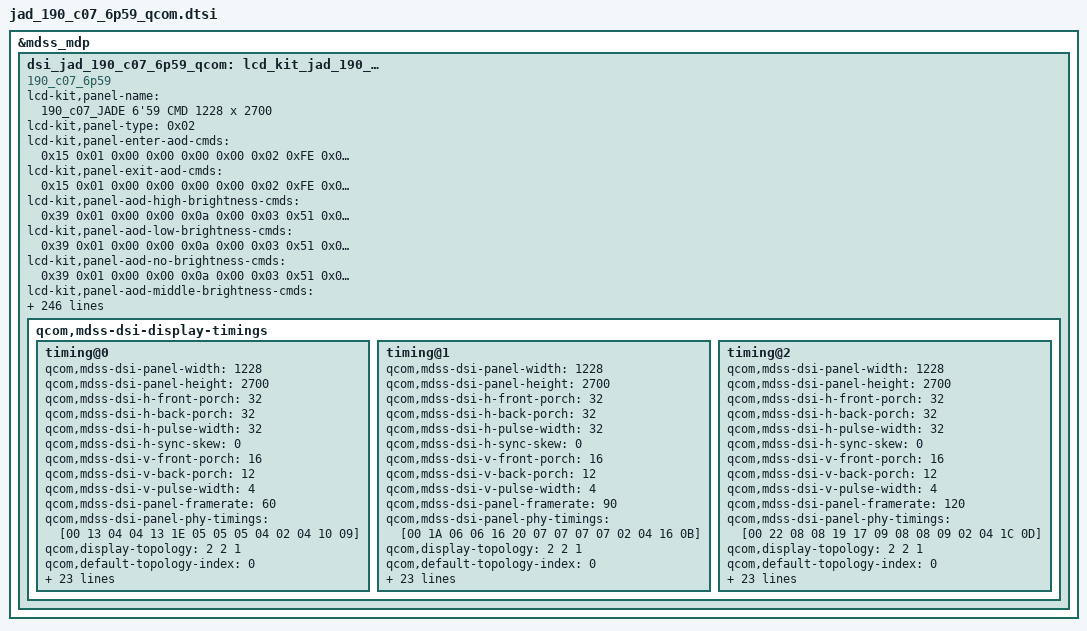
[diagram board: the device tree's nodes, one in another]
/* Copyright (c) 2013, The Linux Foundation. All rights reserved.
 *
 * This program is free software; you can redistribute it and/or modify
 * it under the terms of the GNU General Public License version 2 and
 * only version 2 as published by the Free Software Foundation.
 *
 * This program is distributed in the hope that it will be useful,
 * but WITHOUT ANY WARRANTY; without even the implied warranty of
 * MERCHANTABILITY or FITNESS FOR A PARTICULAR PURPOSE.  See the
 * GNU General Public License for more details.
 */

/*-------------------------------------------------------------------------
 * This file is autogenerated file using gcdb parser. Please do not edit it.
 * Update input XML file to add a new entry or update variable in this file
 * VERSION = 1.1
 *-----------------------------------------------------------------------*/
&mdss_mdp {
	dsi_jad_190_c07_6p59_qcom: lcd_kit_jad_190_c07_6p59_qcom {
		compatible = "190_c07_6p59";
		lcd-kit,panel-name = "190_c07_JADE 6'59 CMD 1228 x 2700";
		lcd-kit,panel-type = <0x02>;
		lcd-kit,panel-enter-aod-cmds = <0x15 0x01 0x00 0x00 0x00 0x00 0x02 0xFE 0x00
			0x05 0x01 0x00 0x00 0x00 0x00 0x01 0x39>;
		lcd-kit,panel-exit-aod-cmds = <0x15 0x01 0x00 0x00 0x00 0x00 0x02 0xFE 0x00
			0x05 0x01 0x00 0x00 0x00 0x00 0x01 0x38>;
		lcd-kit,panel-aod-high-brightness-cmds = <0x39 0x01 0x00 0x00 0x0a 0x00 0x03 0x51 0x0F 0xFE>;
		lcd-kit,panel-aod-low-brightness-cmds = <0x39 0x01 0x00 0x00 0x0a 0x00 0x03 0x51 0x01 0x64>;
		lcd-kit,panel-aod-no-brightness-cmds = <0x39 0x01 0x00 0x00 0x0a 0x00 0x03 0x51 0x00 0x00>;
		lcd-kit,panel-aod-middle-brightness-cmds = <0x39 0x01 0x00 0x00 0x0a 0x00 0x03 0x51 0x07 0x5F>;
		lcd-kit,panel-aod-off-cmds-state = "dsi_lp_mode";
		lcd-kit,pcd-check-reg-cmds = <0x01>;
		lcd-kit,check-reg-on-cmds = <0x06 0x01 0x00 0x00 0x0a 0x00 0x01 0x0a>;
		lcd-kit,check-reg-on-value = <0x9c>;
		lcd-kit,check-aod-reg-on-cmds = <0x06 0x01 0x00 0x00 0x0a 0x00 0x01 0x0a>;
		lcd-kit,check-aod-reg-on-value = <0xdc>;
		lcd-kit,check-reg-off-cmds = <0x06 0x01 0x00 0x00 0x0a 0x00 0x01 0x0a>;
		lcd-kit,check-reg-off-value = <0x08>;
		lcd-kit,check-reg-on-cmds-state = "dsi_lp_mode";
		lcd-kit,check-aod-reg-on-cmds-state = "dsi_lp_mode";
		lcd-kit,check-reg-off-cmds-state = "dsi_lp_mode";
		lcd-kit,pcd-check-reg-value = <0x01>;
		lcd-kit,pcd-errflag-check-support = <0>;
		lcd-kit,checksum-enable-cmds = <0x29 0x01 0x00 0x00 0x14 0x01 0x05 0xFF 0xAA 0x55 0xA5 0x80
			0x15 0x01 0x00 0x00 0x0a 0x00 0x02 0xF2 0x03>;
		lcd-kit,checksum-enable-cmds-state = "dsi_lp_mode";
		lcd-kit,checksum-disable-cmds = <0x29 0x01 0x00 0x00 0x14 0x01 0x05 0xFF 0xAA 0x55 0xA5 0x80
			0x15 0x01 0x00 0x00 0x0a 0x00 0x02 0xF2 0x00>;
		lcd-kit,checksum-disable-cmds-state = "dsi_lp_mode";
		lcd-kit,checksum-cmds = <0x15 0x01 0x00 0x00 0x0a 0x00 0x02 0x6F 0x01
			0x06 0x01 0x00 0x00 0x0a 0x00 0x08 0xF2 0x00 0x00 0x00 0x00 0x00 0x00 0x00>;
		lcd-kit,checksum-cmds-state = "dsi_lp_mode";
		lcd-kit,checksum-value = <0x99 0xb5 0x5c 0x9c 0x39 0x3f 0xb0 0xc3
			0xc2 0xdb 0x34 0xa0 0x85 0xd3 0x81 0xa4
			0xee 0xb1 0x94 0x96 0xda 0x26 0xdf 0x1c>;
		lcd-kit,oneside-mode-left = <0x39 0x01 0x00 0x00 0x00 0x00 0x06 0xF0 0x55 0xAA 0x52 0x08 0x06
		0x39 0x01 0x00 0x00 0x00 0x00 0x06 0xB0 0x32 0x32 0x32 0x32 0x32
		0x39 0x01 0x00 0x00 0x00 0x00 0x06 0xB1 0x32 0x32 0x32 0x32 0x32
		0x39 0x01 0x00 0x00 0x00 0x00 0x06 0xB2 0x32 0x32 0x32 0x32 0x32
		0x15 0x01 0x00 0x00 0x00 0x00 0x02 0xB3 0x32>;
		lcd-kit,oneside-mode-right = <0x39 0x01 0x00 0x00 0x00 0x00 0x06 0xF0 0x55 0xAA 0x52 0x08 0x06
		0x39 0x01 0x00 0x00 0x00 0x00 0x06 0xB6 0x32 0x32 0x32 0x32 0x32
		0x39 0x01 0x00 0x00 0x00 0x00 0x06 0xB7 0x32 0x32 0x32 0x32 0x32
		0x39 0x01 0x00 0x00 0x00 0x00 0x06 0xB8 0x32 0x32 0x32 0x32 0x32
		0x15 0x01 0x00 0x00 0x00 0x00 0x02 0xB9 0x32>;
		lcd-kit,oneside-mode-exit = <0x39 0x01 0x00 0x00 0x00 0x00 0x06 0xF0 0x55 0xAA 0x52 0x08 0x06
		0x39 0x01 0x00 0x00 0x00 0x00 0x06 0xB0 0x28 0x04 0x04 0x13 0x13
		0x39 0x01 0x00 0x00 0x00 0x00 0x06 0xB1 0x12 0x12 0x32 0x00 0x00
		0x39 0x01 0x00 0x00 0x00 0x00 0x06 0xB2 0x0F 0x0F 0x0E 0x0E 0x32
		0x15 0x01 0x00 0x00 0x00 0x00 0x02 0xB3 0x32
		0x39 0x01 0x00 0x00 0x00 0x00 0x06 0xB6 0x28 0x04 0x04 0x13 0x13
		0x39 0x01 0x00 0x00 0x00 0x00 0x06 0xB7 0x12 0x12 0x32 0x00 0x00
		0x39 0x01 0x00 0x00 0x00 0x00 0x06 0xB8 0x0F 0x0F 0x0E 0x0E 0x32
		0x15 0x01 0x00 0x00 0x00 0x00 0x02 0xB9 0x32>;
		lcd-kit,color-aod-detect-enter = <0x15 0x01 0x00 0x00 0x00 0x00 0x02 0xFE 0x00
		0x05 0x01 0x00 0x00 0x00 0x00 0x01 0x39
		0x39 0x01 0x00 0x00 0x00 0x00 0x03 0x51 0x0F 0xFE>;
		lcd-kit,color-aod-detect-enter-state = "dsi_lp_mode";
		lcd-kit,color-aod-detect-exit = <0x15 0x01 0x00 0x00 0x00 0x00 0x02 0xFE 0x00
		0x05 0x01 0x00 0x00 0x00 0x00 0x01 0x38>;
		lcd-kit,color-aod-detect-exit-state = "dsi_lp_mode";
		lcd-kit,hor-line-cmds = <0x39 0x01 0x00 0x00 0x0a 0x00 0x06 0xF0 0x55 0xAA 0x52 0x08 0x00
			0x15 0x01 0x00 0x00 0x0a 0x00 0x02 0xB5 0x90
			0x15 0x01 0x00 0x00 0x0a 0x00 0x02 0x6F 0x06
			0x15 0x01 0x00 0x00 0x0a 0x00 0x02 0xB5 0x4E
			0x39 0x01 0x00 0x00 0x0a 0x00 0x06 0xF0 0x55 0xAA 0x52 0x08 0x01
			0x15 0x01 0x00 0x00 0x0a 0x00 0x02 0xB0 0x03
			0x15 0x01 0x00 0x00 0x0a 0x00 0x02 0xB3 0x15
			0x39 0x01 0x00 0x00 0x0a 0x00 0x06 0xF0 0x55 0xAA 0x52 0x08 0x01
			0x15 0x01 0x00 0x00 0x0a 0x00 0x02 0xB7 0x32
			0x39 0x01 0x00 0x00 0x0a 0x00 0x06 0xF0 0x55 0xAA 0x52 0x08 0x01
			0x15 0x01 0x00 0x00 0x0a 0x00 0x02 0xB1 0x05
			0x15 0x01 0x00 0x00 0x0a 0x00 0x02 0xB4 0x15
			0x39 0x01 0x00 0x00 0x0a 0x00 0x06 0xF0 0x55 0xAA 0x52 0x08 0x01
			0x15 0x01 0x00 0x00 0x0a 0x00 0x02 0xB8 0x5F
			0x29 0x01 0x00 0x00 0x0a 0x00 0x06 0xF0 0x55 0xAA 0x52 0x08 0x01
			0x29 0x01 0x00 0x00 0x0a 0x00 0x03 0xB5 0x00 0xF8
			0x29 0x01 0x00 0x00 0x0a 0x00 0x03 0xB6 0x01 0x68
			0x29 0x01 0x00 0x00 0x0a 0x00 0x06 0xF0 0x55 0xAA 0x52 0x08 0x01
			0x29 0x01 0x00 0x00 0x0a 0x00 0x02 0xCF 0x00
			0x29 0x01 0x00 0x00 0x0a 0x00 0x06 0xF0 0x55 0xAA 0x52 0x08 0x07
			0x29 0x01 0x00 0x00 0x0a 0x00 0x02 0xB0 0x00
			0x39 0x01 0x00 0x00 0x0a 0x00 0x06 0xF0 0x55 0xAA 0x52 0x08 0x06
			0x39 0x01 0x00 0x00 0x0a 0x00 0x06 0xB0 0x28 0x31 0x31 0x13 0x13
			0x39 0x01 0x00 0x00 0x0a 0x00 0x06 0xB1 0x12 0x12 0x32 0x31 0x31
			0x39 0x01 0x00 0x00 0x0a 0x00 0x06 0xB6 0x28 0x31 0x31 0x13 0x13
			0x39 0x01 0x00 0x00 0x0a 0x00 0x06 0xB7 0x12 0x12 0x32 0x31 0x31
			0x39 0x01 0x00 0x00 0x0a 0x00 0x06 0xF0 0x55 0xAA 0x52 0x08 0x03
			0x15 0x01 0x00 0x00 0x0a 0x00 0x02 0x6F 0x0F
			0x15 0x01 0x00 0x00 0x0a 0x00 0x02 0xB6 0x1F
			0x15 0x01 0x00 0x00 0x0a 0x00 0x02 0x6F 0x18
			0x15 0x01 0x00 0x00 0x0a 0x00 0x02 0xB6 0x0F
			0x15 0x01 0x00 0x00 0x0a 0x00 0x02 0x6F 0x21
			0x15 0x01 0x00 0x00 0x0a 0x00 0x02 0xB6 0x0F
			0x15 0x01 0x00 0x00 0x0a 0x00 0x02 0x6F 0x2A
			0x15 0x01 0x00 0x00 0x0a 0x00 0x02 0xB6 0x0F
			0x05 0x01 0x00 0x00 0x0a 0x00 0x01 0x35
			0x15 0x01 0x00 0x00 0x0a 0x00 0x02 0x53 0x20
			0x39 0x01 0x00 0x00 0x0a 0x00 0x05 0x51 0x00 0x00 0x00 0x00
			0x39 0x01 0x00 0x00 0x0a 0x00 0x05 0x2A 0x00 0x00 0x04 0xCB
			0x39 0x01 0x00 0x00 0x0a 0x00 0x05 0x2B 0x00 0x00 0x0A 0x8B
			0x15 0x01 0x00 0x00 0x0a 0x00 0x02 0x90 0x01
			0x15 0x01 0x00 0x00 0x0a 0x00 0x02 0x03 0x01
			0x39 0x01 0x00 0x00 0x64 0x00 0x13 0x91 0x89 0x28 0x00 0x3C 0xF2 0x00 0x04 0x01 0x06 0xF5 0x00 0x11 0x02 0x09 0x00 0xBF 0x10 0xF0
			0x05 0x01 0x00 0x00 0x0a 0x00 0x01 0x2C
			0x15 0x01 0x00 0x00 0x0a 0x00 0x02 0x82 0xAC
			0x05 0x01 0x00 0x00 0x46 0x01 0x01 0x11
			0x15 0x01 0x00 0x00 0x0a 0x00 0x02 0x2F 0x01
			0x05 0x01 0x00 0x00 0x0a 0x00 0x01 0x29>;
		lcd-kit,hor-line-cmds-state = "dsi_lp_mode";
		lcd-kit,pcd-read-cmds = <0x15 0x01 0x00 0x00 0x00 0x00 0x02 0xFE 0x40
		0x15 0x01 0x00 0x00 0x00 0x00 0x02 0x5D 0x28
		0x15 0x01 0x00 0x00 0x00 0x00 0x02 0x51 0x5A
		0x06 0x01 0x00 0x00 0x00 0x00 0x01 0xDB>;
		lcd-kit,pcd-read-cmds-state  = "dsi_lp_mode";
		lcd-kit,vtc-line-cmds = <0x39 0x01 0x00 0x00 0x00 0x00 0x06 0xF0 0x55 0xAA 0x52 0x08 0x03
			0x15 0x01 0x00 0x00 0x00 0x00 0x02 0x6F 0x0F
			0x15 0x01 0x00 0x00 0x00 0x00 0x02 0xB6 0x1F
			0x15 0x01 0x00 0x00 0x00 0x00 0x02 0x6F 0x18
			0x15 0x01 0x00 0x00 0x00 0x00 0x02 0xB6 0x0F
			0x15 0x01 0x00 0x00 0x00 0x00 0x02 0x6F 0x21
			0x15 0x01 0x00 0x00 0x00 0x00 0x02 0xB6 0x0F
			0x15 0x01 0x00 0x00 0x00 0x00 0x02 0x6F 0x2A
			0x15 0x01 0x00 0x00 0x00 0x00 0x02 0xB6 0x0F
			0x05 0x01 0x00 0x00 0x00 0x00 0x01 0x35
			0x15 0x01 0x00 0x00 0x00 0x00 0x02 0x53 0x20
			0x39 0x01 0x00 0x00 0x00 0x00 0x05 0x51 0x0D 0xBB 0x00 0x00
			0x39 0x01 0x00 0x00 0x00 0x00 0x05 0x2A 0x00 0x00 0x04 0xCB
			0x39 0x01 0x00 0x00 0x00 0x00 0x05 0x2B 0x00 0x00 0x0A 0x8B
			0x15 0x01 0x00 0x00 0x00 0x00 0x02 0x90 0x01
			0x15 0x01 0x00 0x00 0x00 0x00 0x02 0x03 0x01
			0x39 0x01 0x00 0x00 0x01 0x00 0x13 0x91 0x89 0x28 0x00 0x3C 0xF2 0x00 0x04 0x01 0x06 0xF5 0x00 0x11 0x02 0x09 0x00 0xBF 0x10 0xF0
			0x05 0x01 0x00 0x00 0x00 0x00 0x01 0x2C
			0x15 0x01 0x00 0x00 0x00 0x00 0x02 0x82 0xAC
			0x15 0x01 0x00 0x00 0x00 0x00 0x02 0x2F 0x01
			0x39 0x01 0x00 0x00 0x00 0x00 0x06 0xF0 0x55 0xAA 0x52 0x08 0x00
			0x15 0x01 0x00 0x00 0x00 0x00 0x02 0xB5 0x94
			0x15 0x01 0x00 0x00 0x00 0x00 0x02 0x6F 0x06
			0x39 0x01 0x00 0x00 0x00 0x00 0x04 0xB5 0x4E 0x23 0x50
			0x15 0x01 0x00 0x00 0x00 0x00 0x02 0x6F 0x0B
			0x39 0x01 0x00 0x00 0x00 0x00 0x04 0xB5 0x4E 0x2A 0x50
			0x15 0x01 0x00 0x00 0x00 0x00 0x02 0x6F 0x10
			0x39 0x01 0x00 0x00 0x00 0x00 0x06 0xB5 0x23 0x23 0x23 0x23 0x23
			0x39 0x01 0x00 0x00 0x00 0x00 0x05 0xBE 0x0E 0x09 0x14 0x13
			0x39 0x01 0x00 0x00 0x00 0x00 0x06 0xF0 0x55 0xAA 0x52 0x08 0x01
			0x39 0x01 0x00 0x00 0x00 0x00 0x04 0xD1 0x07 0x4A 0x40
			0x15 0x01 0x00 0x00 0x00 0x00 0x02 0x6F 0x02
			0x15 0x01 0x00 0x00 0x00 0x00 0x02 0xD2 0x11
			0x05 0x01 0x00 0x00 0x46 0x00 0x01 0x11
			0x05 0x01 0x00 0x00 0x00 0x00 0x01 0x29>;
		lcd-kit,vtc-line-cmds-state  = "dsi_lp_mode";
		lcd-kit,ddic-lv-det-enter1-cmds = <0x39 0x01 0x00 0x00 0x0a 0x00 0x06 0xF0 0x55 0xAA 0x52 0x08 0x01
			0x15 0x01 0x00 0x00 0x0a 0x00 0x02 0xC7 0xA0
			0x15 0x01 0x00 0x00 0x0a 0x00 0x02 0x6F 0x03
			0x15 0x01 0x00 0x00 0x0a 0x00 0x02 0xC7 0x18>;
		lcd-kit,ddic-lv-det-enter1-cmds-state  = "dsi_lp_mode";
		lcd-kit,ddic-lv-det-enter2-cmds = <0x39 0x01 0x00 0x00 0x0a 0x00 0x06 0xF0 0x55 0xAA 0x52 0x08 0x01
			0x15 0x01 0x00 0x00 0x0a 0x00 0x02 0xC7 0xA0
			0x15 0x01 0x00 0x00 0x0a 0x00 0x02 0x6F 0x03
			0x15 0x01 0x00 0x00 0x0a 0x00 0x02 0xC7 0x18>;
		lcd-kit,ddic-lv-det-enter2-cmds-state  = "dsi_lp_mode";
		lcd-kit,ddic-lv-det-enter3-cmds = <0x39 0x01 0x00 0x00 0x0a 0x00 0x06 0xF0 0x55 0xAA 0x52 0x08 0x01
			0x15 0x01 0x00 0x00 0x0a 0x00 0x02 0xC7 0xA0
			0x15 0x01 0x00 0x00 0x0a 0x00 0x02 0x6F 0x03
			0x15 0x01 0x00 0x00 0x0a 0x00 0x02 0xC7 0x18>;
		lcd-kit,ddic-lv-det-enter3-cmds-state  = "dsi_lp_mode";
		lcd-kit,ddic-lv-det-enter4-cmds = <0x39 0x01 0x00 0x00 0x0a 0x00 0x06 0xF0 0x55 0xAA 0x52 0x08 0x01
			0x15 0x01 0x00 0x00 0x0a 0x00 0x02 0xC7 0xA0
			0x15 0x01 0x00 0x00 0x0a 0x00 0x02 0x6F 0x03
			0x15 0x01 0x00 0x00 0x0a 0x00 0x02 0xC7 0x18>;
		lcd-kit,ddic-lv-det-enter4-cmds-state  = "dsi_lp_mode";
		lcd-kit,ddic-lv-det-rd1-cmds = <0x06 0x01 0x00 0x00 0x0a 0x00 0x01 0x0a>;
		lcd-kit,ddic-lv-det-rd1-cmds-state  = "dsi_lp_mode";
		lcd-kit,ddic-lv-det-rd2-cmds = <0x06 0x01 0x00 0x00 0x0a 0x00 0x01 0x0a>;
		lcd-kit,ddic-lv-det-rd2-cmds-state  = "dsi_lp_mode";
		lcd-kit,ddic-lv-det-rd3-cmds = <0x06 0x01 0x00 0x00 0x0a 0x00 0x01 0x0a>;
		lcd-kit,ddic-lv-det-rd3-cmds-state  = "dsi_lp_mode";
		lcd-kit,ddic-lv-det-rd4-cmds = <0x06 0x01 0x00 0x00 0x0a 0x00 0x01 0x0a>;
		lcd-kit,ddic-lv-det-rd4-cmds-state  = "dsi_lp_mode";
		lcd-kit,ddic-lv-det-value1 = <0x9c>;
		lcd-kit,ddic-lv-det-value2 = <0x9c>;
		lcd-kit,ddic-lv-det-value3 = <0x9c>;
		lcd-kit,ddic-lv-det-value4 = <0x9c>;
		lcd-kit,bl-after-frame = <0>;
		lcd-kit,cmd-async-support = <0>;
		lcd-kit,ap-aod-support = <1>;
		lcd-kit,left-time-to-te-us = <25667>;
		lcd-kit,right-time-to-te-us = <26167>;
		lcd-kit,te-interval-time-us = <16667>;
		lcd-kit,oneside-mode-support = <0>;
		lcd-kit,color-aod-detect-support = <1>;
		lcd-kit,elvdd-detect-support = <0>;
		lcd-kit,elvdd-detect-type = <2>;
		lcd-kit,elvdd-detect-value = <1>;
		lcd-kit,elvdd-delay = <50>;
		lcd-kit,elvdd-detect-gpio = <104>;
		lcd-kit,check-reg-on-support = <0>;
		lcd-kit,check-reg-on-support-dsm-report = <0>;
		lcd-kit,check-aod-reg-on-support = <0>;
		lcd-kit,check-aod-reg-on-support-dsm-report = <0>;
		lcd-kit,check-reg-off-support = <0>;
		lcd-kit,check-reg-off-support-dsm-report = <0>;
		lcd-kit,checksum-support = <0>;
		lcd-kit,pcd-cmds-support = <1>;
		lcd-kit,pcd-check-reg-value-compare-mode = <0>;
		lcd-kit,vtc-line-support = <0>;
		lcd-kit,ddic-lv-det-support = <0>;
		lcd-kit,hor-line-support = <0>;
		lcd-kit,hor-line-duration = <600>;
		lcd-kit,vtc-line-no-reset = <1>;
		qcom,mdss-dsi-panel-type = "dsi_cmd_mode";
		qcom,mdss-pan-physical-width-dimension = <69>;
		qcom,mdss-pan-physical-height-dimension = <154>;
		qcom,dsi-ctrl-num = <0>;
		qcom,dsi-phy-num = <0>;
		qcom,panel-supply-entries = <&dsi_panel_pwr_supply>;
		qcom,mdss-dsi-virtual-channel-id = <0>;
		qcom,mdss-dsi-h-sync-pulse = <0>;
		qcom,mdss-dsi-bllp-eof-power-mode;
		qcom,mdss-dsi-bllp-power-mode;
		qcom,mdss-dsi-dma-schedule-line = <1>;
		qcom,mdss-dsi-bpp = <24>;
		qcom,mdss-dsi-color-order = "rgb_swap_rgb";
		qcom,mdss-dsi-underflow-color = <0xff>;
		qcom,mdss-dsi-border-color = <0>;
		qcom,mdss-dsi-traffic-mode = "burst_mode";
		qcom,mdss-dsi-lane-map = "lane_map_0123";
		qcom,mdss-dsi-lane-0-state;
		qcom,mdss-dsi-lane-1-state;
		qcom,mdss-dsi-lane-2-state;
		qcom,mdss-dsi-lane-3-state;
		qcom,mdss-dsi-mdp-trigger = "none";
		qcom,mdss-dsi-dma-trigger = "trigger_sw";
		qcom,mdss-dsi-te-pin-select = <1>;
		qcom,mdss-dsi-wr-mem-start = <0x2c>;
		qcom,mdss-dsi-wr-mem-continue = <0x3c>;
		qcom,mdss-dsi-te-dcs-command = <1>;
		qcom,mdss-dsi-te-check-enable;
		qcom,mdss-dsi-te-using-te-pin;
		qcom,dsi-panel-gpio-address = <0x0F100000 0x1000>;
		qcom,dsi-panel-gpio-pins = <12 24 82>;
		qcom,dsi-panel-gpio-names = "reg-gpio", "reset-gpio", "platform-te-gpio";
		qcom,mdss-dsi-t-clk-post = <0>;
		qcom,mdss-dsi-t-clk-pre = <0>;
		qcom,dsi-select-clocks = "mux_byte_clk0", "mux_pixel_clk0";
		qcom,mdss-dsi-stream = <0>;
		qcom,mdss-dsi-lp11-init;
		lcd-kit,check-thread-support = <0>;
		lcd-kit,check-time-period = <5000>;
		lcd-kit,check-fold-support = <0>;
		lcd-kit,fold-low-power-support = <0>;
		lcd-kit,fold-height = <0>;
		lcd-kit,unfold-height = <0>;
		lcd-kit,power-support = <0>;
		lcd-kit,three-stage-poweron = <0>;
		qcom,apaod-lp2-need-sendcmd;
		lcd-kit,fold-lp-time = <0>;
		lcd-kit,fold-nolp-time = <0>;
		qcom,sublinks-count = <2>;
		qcom,lanes-per-sublink = <2>;
		qcom,mdss-dsi-panel-hdr-color-primaries = <14500 15500 32000 17000 15500 30000 8000 3000>;
		qcom,mdss-dsi-panel-peak-brightness = <4200000>;
		qcom,mdss-dsi-panel-blackness-level = <3230>;
		qcom,dynamic-mode-switch-enabled;
		qcom,dynamic-mode-switch-type = "dynamic-resolution-switch-immediate";
		qcom,mdss-dsi-bl-pmic-control-type = "bl_ctrl_dcs";
		qcom,mdss-dsi-bl-min-level = <1>;
		qcom,mdss-dsi-bl-max-level = <4095>;
		qcom,esd-check-enabled;
		qcom,mdss-dsi-panel-status-command = [06 01 00 00 00 00 01 0A
		06 01 00 00 00 00 01 FA];
		qcom,mdss-dsi-panel-status-command-state = "dsi_lp_mode";
		qcom,mdss-dsi-panel-status-check-mode = "reg_read";
		qcom,mdss-dsi-panel-status-read-length = <1 1>;
		qcom,mdss-dsi-panel-status-value = <0x9C>, <0x01>;
		lcd-kit,power-on-stage = <2 1 1
				9 1 3
				3 1 3
				1 1 1
				5 1 1
				5 0 1
				5 1 32
				7 1 0
				6 1 0
				8 1 0>;
		lcd-kit,lp-on-stage = <0 0 0>;
		lcd-kit,lp-off-stage = <0 0 0>;
		lcd-kit,power-off-stage = <7 0 0
				6 0 0
				8 0 0
				5 0 2
				1 0 2
				9 0 1
				3 0 1
				2 0 5>;
		lcd-kit,only-power-off-stage = <0 0 0>;
		lcd-kit,pt-support = <1>;
		lcd-kit,panel-on-always-reset = <0>;
		lcd-kit,lcd-vci = <1 13 3000000 3000000 3000000 10000 80>;
		lcd-kit,lcd-iovcc = <1 12 1800000 1800000 1800000 60700 80>;
		lcd-kit,lcd-vdd = <2 197 1200000>;
		lcd-kit,lcd-vsp = <1 1 1200000 1200000 1200000 60700 80>;
		lcd-kit,lcd-reset = <2 24 0>;
		lcd-kit,lcd-vci-name = "vdd";
		lcd-kit,lcd-iovcc-name = "vddio";
		lcd-kit,lcd-vsp-name = "ddic";
		lcd-kit,project-id-support = <0>;
		lcd-kit,default-project-id = "G240A7130";
		lcd-kit,sn-code-support = <1>;
		lcd-kit,oem-info-support = <1>;
		lcd-kit,oem-barcode-2d-support = <1>;
		lcd-kit,oem-barcode-2d-num-offset = <0>;
		lcd-kit,barcode-2d-cmds = <0x15 0x01 0x00 0x00 0x0a 0x00 0x02 0xFE 0xC2
				0x14 0x01 0x00 0x00 0x0a 0x00 0x01 0x02
				0x14 0x01 0x00 0x00 0x0a 0x00 0x01 0x03
				0x14 0x01 0x00 0x00 0x0a 0x00 0x01 0x04
				0x14 0x01 0x00 0x00 0x0a 0x00 0x01 0x05
				0x14 0x01 0x00 0x00 0x0a 0x00 0x01 0x06
				0x14 0x01 0x00 0x00 0x0a 0x00 0x01 0x07
				0x14 0x01 0x00 0x00 0x0a 0x00 0x01 0x08
				0x14 0x01 0x00 0x00 0x0a 0x00 0x01 0x09
				0x14 0x01 0x00 0x00 0x0a 0x00 0x01 0x0A
				0x14 0x01 0x00 0x00 0x0a 0x00 0x01 0x0B
				0x14 0x01 0x00 0x00 0x0a 0x00 0x01 0x0C
				0x14 0x01 0x00 0x00 0x0a 0x00 0x01 0x0D
				0x14 0x01 0x00 0x00 0x0a 0x00 0x01 0x0E
				0x14 0x01 0x00 0x00 0x0a 0x00 0x01 0x0F
				0x14 0x01 0x00 0x00 0x0a 0x00 0x01 0x10
				0x14 0x01 0x00 0x00 0x0a 0x00 0x01 0x11
				0x14 0x01 0x00 0x00 0x0a 0x00 0x01 0x12
				0x14 0x01 0x00 0x00 0x0a 0x00 0x01 0x13
				0x14 0x01 0x00 0x00 0x0a 0x00 0x01 0x14
				0x14 0x01 0x00 0x00 0x0a 0x00 0x01 0x15
				0x14 0x01 0x00 0x00 0x0a 0x00 0x01 0x16
				0x15 0x01 0x00 0x00 0x0a 0x00 0x02 0xFE 0x00>;
		lcd-kit,barcode-2d-cmds-state = "dsi_lp_mode";
		lcd-kit,panel-getblmaxnit-type = <0>;
		lcd-kit,panel-blmaxnit-min-value = <400>;
		lcd-kit,inversion-support = <0>;
		lcd-kit,panel-gpio-offset = <308>;
		lcd-kit,finger-unlock-state-support = <0>;
		lcd-kit,esd-reg-te-check = <0>;
		lcd-kit,panel-bl-max-nit = <450>;
		lcd-kit,panel-bl-min = <3>;
		lcd-kit,panel-bl-max = <10000>;
		lcd-kit,panel-bl-def = <2074>;
		lcd-kit,check-reg-support = <0>;
		lcd-kit,thp-proximity-support = <0>;
		lcd-kit,proximity-reset-delay-min = <65>;
		lcd-kit,backlight-cmds = <0x39 0x01 0x00 0x00 0x00 0x00 0x03 0x51 0x00 0x00>;
		lcd-kit,backlight-cmds-state = "dsi_lp_mode";
		lcd-kit,backlight-order = <0>;
		lcd-kit,backlight-need-sync = <0>;
		lcd-kit,fps-support = <1>;
		lcd-kit,default-fps = <60>;
		lcd-kit,panel-support-fps-list = <60 90 120>;
		lcd-kit,fps-60-cmd = "vndservice call display.qservice 25 i32 0 i32 0";
		lcd-kit,fps-90-cmd = "vndservice call display.qservice 25 i32 2 i32 0";
		lcd-kit,fps-120-cmd = "vndservice call display.qservice 25 i32 1 i32 0";
		qcom,mdss-dsi-display-timings {
			timing@0 {
				qcom,mdss-dsi-panel-width = <1228>;
				qcom,mdss-dsi-panel-height = <2700>;
				qcom,mdss-dsi-h-front-porch = <32>;
				qcom,mdss-dsi-h-back-porch = <32>;
				qcom,mdss-dsi-h-pulse-width = <32>;
				qcom,mdss-dsi-h-sync-skew = <0>;
				qcom,mdss-dsi-v-front-porch = <16>;
				qcom,mdss-dsi-v-back-porch = <12>;
				qcom,mdss-dsi-v-pulse-width = <4>;
				qcom,mdss-dsi-panel-framerate = <60>;
				qcom,mdss-dsi-panel-phy-timings= [00 13 04 04 13 1E 05
			05 05 04 02 04 10 09];
				qcom,display-topology  = <2 2 1>;
				qcom,default-topology-index  = <0>;
				qcom,mdss-dsi-on-command = [
		39 01 00 00 00 00 02 FE 40
		39 01 00 00 00 00 02 24 55
		39 01 00 00 00 00 02 A9 14
		39 01 00 00 00 00 02 AD C8
		39 01 00 00 00 00 02 A5 20
		39 01 00 00 00 00 02 AC 04
		39 01 00 00 00 00 02 AE 70
		39 01 00 00 00 00 02 AF 00
		39 01 00 00 00 00 02 B0 00
		39 01 00 00 00 00 02 B2 00
		39 01 00 00 00 00 02 B3 50
		39 01 00 00 00 00 02 FE 26
		39 01 00 00 00 00 02 1D 2A
		39 01 00 00 00 00 02 A4 23
		39 01 00 00 00 00 02 FE 41
		39 01 00 00 00 00 02 D6 04
		39 01 00 00 00 00 02 FE 00
		39 01 00 00 00 00 65 77 4D 43 39 25 11 25 39 43 4D 43 39 25 11 11 25 39 43 4D 43 39 25 11 25 39 43 4D 39 43 4D 43 39 25 11 25 39 43 4D 43 39 4D 43 25 11 11 25 43 39 25 11 4D 43 39 11 25 39 43 4D 43 39 25 11 25 39 43 4D 39 43 4D 43 39 25 11 25 39 43 4D 43 39 4D 43 25 11 11 25 43 39 25 11 4D 43 39 4D 43 39 25 11 25 39 43 4D
		39 01 00 00 00 00 65 78 43 39 25 11 39 43 4D 43 39 25 11 25 39 43 4D 43 39 4D 43 25 11 11 25 43 39 25 11 4D 43 39 4D 43 39 25 11 25 39 43 4D 43 39 25 11 11 25 39 43 4D 43 39 25 11 25 39 43 4D 4D 43 25 11 11 25 43 39 25 11 4D 43 39 4D 43 39 25 11 25 39 43 4D 43 39 25 11 11 25 39 43 4D 43 39 25 11 25 39 43 4D 39 43 4D 43 39
		39 01 00 00 00 00 65 78 25 11 25 39 43 4D 43 39 11 25 39 43 4D 43 39 25 11 25 39 4B 4D 4D 43 39 25 11 25 39 43 4D 43 39 25 11 39 43 4D 43 39 25 11 25 39 43 4D 43 39 43 39 25 11 4D 43 43 25 11 25 39 43 4D 4D 43 39 25 11 25 39 43 4D 43 39 25 11 39 43 4D 43 39 25 11 25 39 43 4D 43 39 43 39 25 11 4D 43 43 25 11 25 39 43 4D 11
		39 01 00 00 00 00 65 78 25 39 43 4D 43 39 25 11 25 39 43 4D 39 43 4D 43 39 25 11 25 39 43 4D 43 39 43 39 25 11 4D 43 43 25 11 25 39 43 4D 11 25 39 43 4D 43 39 25 11 25 39 43 4D 4D 43 39 25 11 25 39 43 4D 43 39 25 11 43 39 25 11 4D 43 43 25 11 25 39 43 4D 11 25 39 43 4D 43 39 25 11 25 39 43 4D 4D 43 39 25 11 25 39 43 4D 43
		39 01 00 00 00 00 65 78 39 25 11 39 43 4D 43 39 25 11 25 39 43 4D 43 39 39 43 4D 43 39 25 11 25 39 43 4D 43 39 11 25 39 43 4D 43 39 25 11 25 39 43 4D 39 43 4D 43 39 25 11 25 39 43 4D 43 39 4D 43 43 25 11 25 43 39 25 11 4D 43 39 11 25 39 43 4D 43 39 25 11 25 39 43 4D 39 43 4D 43 39 25 11 25 39 43 4D 43 39 4D 43 43 25 11 25
		39 01 00 00 00 00 65 78 43 39 25 11 4D 43 39 39 43 4D 43 39 25 11 25 39 43 4D 43 39 39 43 4D 43 39 25 11 25 39 43 4D 43 39 4D 43 43 25 11 25 43 39 25 11 4D 43 39 39 43 4D 43 39 25 11 25 39 43 4D 43 39 11 25 39 43 4D 43 39 25 11 25 39 43 4D 4D 43 43 25 11 25 43 39 25 11 4D 43 39 39 43 4D 43 39 25 11 25 39 43 4D 43 39 11 25
		39 01 00 00 00 00 66 78 39 43 4D 43 39 25 11 25 39 43 4D 39 43 4D 43 39 25 11 25 39 43 4D 43 39 28 28 28 28 28 28 27 26 24 23 16 16 16 1F 1E 21 25 29 01 05 08 0B 0E 11 14 18 21 25 29 01 03 05 07 18 05 08 0B 0E 11 05 08 0B 1B 1E 21 25 29 01 05 08 0B 0E 28 28 28 28 28 28 27 26 24 23 16 16 16 21 25 29 01 03 05 07 18 05 08 0B 0E
		39 01 00 00 00 00 66 78 11 05 08 0B 1B 1E 21 25 29 01 05 08 0B 0E 01 05 08 0B 0E 11 14 18 1B 1E 21 25 29 28 28 28 28 28 28 27 26 24 23 16 16 16 05 08 0B 1B 1E 21 25 29 01 05 08 0B 0E 01 05 08 0B 0E 11 14 18 1B 1E 21 25 29 1B 1E 21 25 29 01 05 08 0B 0E 11 14 18 28 28 28 28 28 28 27 26 24 23 16 16 16 01 05 08 0B 0E 11 14 18 1B
		39 01 00 00 00 00 1F 78 1E 21 25 29 1B 1E 21 25 29 01 05 08 0B 0E 11 14 18 21 25 29 01 03 05 07 18 05 08 0B 0E 11
		39 01 00 00 00 00 02 FE 41
		39 01 00 00 00 00 02 D6 00
		15 01 00 00 00 00 02 FE 60
		15 01 00 00 00 00 02 88 0D
		15 01 00 00 00 00 02 91 0D
		15 01 00 00 00 00 02 9A 0D
		15 01 00 00 00 00 02 A4 0D
		15 01 00 00 00 00 02 FE 98
		15 01 00 00 00 00 02 13 06
		15 01 00 00 00 00 02 FE 36
		15 01 00 00 00 00 02 EC 00
		15 01 00 00 00 00 02 07 A0
		15 01 00 00 00 00 02 08 A0
		15 01 00 00 00 00 02 09 02
		15 01 00 00 00 00 02 FE A1
		15 01 00 00 00 00 02 B5 04
		15 01 00 00 00 00 02 FE 62
		15 01 00 00 00 00 02 4E 00
		15 01 00 00 00 00 02 FE 40
		15 01 00 00 00 00 02 B6 02
		15 01 00 00 00 00 02 23 00
		15 01 00 00 00 00 02 24 54
		15 01 00 00 00 00 02 47 22
		15 01 00 00 00 00 02 48 13
		15 01 00 00 00 00 02 FE FD
		15 01 00 00 00 00 02 80 F6
		15 01 00 00 00 00 02 FE D1
		15 01 00 00 00 00 02 F5 30
		15 01 00 00 00 00 02 F9 00
		15 01 00 00 00 00 02 F7 80
		15 01 00 00 00 00 02 FE 83
		15 01 00 00 00 00 02 0C 4F
		15 01 00 00 00 00 02 0D 7E
		15 01 00 00 00 00 02 0E FF
		15 01 00 00 00 00 02 0F 7E
		15 01 00 00 00 00 02 10 7E
		15 01 00 00 00 00 02 11 FF
		15 01 00 00 00 00 02 12 7E
		15 01 00 00 00 00 02 13 7E
		15 01 00 00 00 00 02 14 FF
		15 01 00 00 00 00 02 15 7E
		15 01 00 00 00 00 02 16 7E
		15 01 00 00 00 00 02 17 FF
		15 01 00 00 00 00 02 18 7E
		15 01 00 00 00 00 02 19 7E
		15 01 00 00 00 00 02 1A FF
		15 01 00 00 00 00 02 1B 7E
		15 01 00 00 00 00 02 1C 7E
		15 01 00 00 00 00 02 FE F9
		15 01 00 00 00 00 02 00 AF
		15 01 00 00 00 00 02 1D 1F
		15 01 00 00 00 00 02 FE 00
		15 01 00 00 00 00 02 FA 01
		15 01 00 00 00 00 02 C2 08
		15 01 00 00 00 00 02 35 00
		39 01 00 00 00 00 03 51 00 00
		15 01 00 00 00 00 02 FE 40
		15 01 00 00 00 00 02 BD 00
		15 01 00 00 00 00 02 FE 00
		05 01 00 00 78 00 01 11
		05 01 00 00 00 00 01 29];
				qcom,mdss-dsi-on-command-state = "dsi_lp_mode";
				qcom,mdss-dsi-off-command = [15 01 00 00 00 00 02 FE 00
			05 01 00 00 23 00 01 28
			05 01 00 00 64 00 01 10];
				qcom,mdss-dsi-off-command-state = "dsi_lp_mode";
				qcom,compression-mode = "dsc";
				qcom,mdss-dsc-slice-height = <60>;
				qcom,mdss-dsc-slice-width = <614>;
				qcom,mdss-dsc-slice-per-pkt = <2>;
				qcom,mdss-dsc-bit-per-component = <8>;
				qcom,mdss-dsc-bit-per-pixel = <8>;
				qcom,mdss-dsc-block-prediction-enable;
				qcom,mdss-dsi-timing-switch-command = [15 01 00 00 00 00 02 FE 40
			15 01 00 00 00 00 02 BD 00
			15 01 00 00 11 00 02 FE 00];
				qcom,mdss-dsi-timing-switch-command-state = "dsi_lp_mode";
				qcom,mdss-dsi-lp1-command = [15 01 00 00 00 00 02 FE 00
			05 01 00 00 00 00 01 39];
				qcom,mdss-dsi-lp1-command-state = "dsi_lp_mode";
				qcom,mdss-dsi-nolp-command = [15 01 00 00 00 00 02 FE 00
			39 01 00 00 00 00 03 51 00 00
			05 01 00 00 00 00 01 38
			15 01 00 00 00 00 02 FE 40
			15 01 00 00 00 00 02 BD 00
			15 01 00 00 11 00 02 FE 00];
				qcom,mdss-dsi-nolp-command-state = "dsi_lp_mode";
			};
			timing@1 {
				qcom,mdss-dsi-panel-width = <1228>;
				qcom,mdss-dsi-panel-height = <2700>;
				qcom,mdss-dsi-h-front-porch = <32>;
				qcom,mdss-dsi-h-back-porch = <32>;
				qcom,mdss-dsi-h-pulse-width = <32>;
				qcom,mdss-dsi-h-sync-skew = <0>;
				qcom,mdss-dsi-v-front-porch = <16>;
				qcom,mdss-dsi-v-back-porch = <12>;
				qcom,mdss-dsi-v-pulse-width = <4>;
				qcom,mdss-dsi-panel-framerate = <90>;
				qcom,mdss-dsi-panel-phy-timings= [00 1A 06 06 16 20 07
			07 07 07 02 04 16 0B];
				qcom,display-topology  = <2 2 1>;
				qcom,default-topology-index  = <0>;
				qcom,mdss-dsi-on-command = [
		39 01 00 00 00 00 02 FE 40
		39 01 00 00 00 00 02 24 55
		39 01 00 00 00 00 02 A9 14
		39 01 00 00 00 00 02 AD C8
		39 01 00 00 00 00 02 A5 20
		39 01 00 00 00 00 02 AC 04
		39 01 00 00 00 00 02 AE 70
		39 01 00 00 00 00 02 AF 00
		39 01 00 00 00 00 02 B0 00
		39 01 00 00 00 00 02 B2 00
		39 01 00 00 00 00 02 B3 50
		39 01 00 00 00 00 02 FE 26
		39 01 00 00 00 00 02 1D 2A
		39 01 00 00 00 00 02 A4 23
		39 01 00 00 00 00 02 FE 41
		39 01 00 00 00 00 02 D6 04
		39 01 00 00 00 00 02 FE 00
		39 01 00 00 00 00 65 77 4D 43 39 25 11 25 39 43 4D 43 39 25 11 11 25 39 43 4D 43 39 25 11 25 39 43 4D 39 43 4D 43 39 25 11 25 39 43 4D 43 39 4D 43 25 11 11 25 43 39 25 11 4D 43 39 11 25 39 43 4D 43 39 25 11 25 39 43 4D 39 43 4D 43 39 25 11 25 39 43 4D 43 39 4D 43 25 11 11 25 43 39 25 11 4D 43 39 4D 43 39 25 11 25 39 43 4D
		39 01 00 00 00 00 65 78 43 39 25 11 39 43 4D 43 39 25 11 25 39 43 4D 43 39 4D 43 25 11 11 25 43 39 25 11 4D 43 39 4D 43 39 25 11 25 39 43 4D 43 39 25 11 11 25 39 43 4D 43 39 25 11 25 39 43 4D 4D 43 25 11 11 25 43 39 25 11 4D 43 39 4D 43 39 25 11 25 39 43 4D 43 39 25 11 11 25 39 43 4D 43 39 25 11 25 39 43 4D 39 43 4D 43 39
		39 01 00 00 00 00 65 78 25 11 25 39 43 4D 43 39 11 25 39 43 4D 43 39 25 11 25 39 4B 4D 4D 43 39 25 11 25 39 43 4D 43 39 25 11 39 43 4D 43 39 25 11 25 39 43 4D 43 39 43 39 25 11 4D 43 43 25 11 25 39 43 4D 4D 43 39 25 11 25 39 43 4D 43 39 25 11 39 43 4D 43 39 25 11 25 39 43 4D 43 39 43 39 25 11 4D 43 43 25 11 25 39 43 4D 11
		39 01 00 00 00 00 65 78 25 39 43 4D 43 39 25 11 25 39 43 4D 39 43 4D 43 39 25 11 25 39 43 4D 43 39 43 39 25 11 4D 43 43 25 11 25 39 43 4D 11 25 39 43 4D 43 39 25 11 25 39 43 4D 4D 43 39 25 11 25 39 43 4D 43 39 25 11 43 39 25 11 4D 43 43 25 11 25 39 43 4D 11 25 39 43 4D 43 39 25 11 25 39 43 4D 4D 43 39 25 11 25 39 43 4D 43
		39 01 00 00 00 00 65 78 39 25 11 39 43 4D 43 39 25 11 25 39 43 4D 43 39 39 43 4D 43 39 25 11 25 39 43 4D 43 39 11 25 39 43 4D 43 39 25 11 25 39 43 4D 39 43 4D 43 39 25 11 25 39 43 4D 43 39 4D 43 43 25 11 25 43 39 25 11 4D 43 39 11 25 39 43 4D 43 39 25 11 25 39 43 4D 39 43 4D 43 39 25 11 25 39 43 4D 43 39 4D 43 43 25 11 25
		39 01 00 00 00 00 65 78 43 39 25 11 4D 43 39 39 43 4D 43 39 25 11 25 39 43 4D 43 39 39 43 4D 43 39 25 11 25 39 43 4D 43 39 4D 43 43 25 11 25 43 39 25 11 4D 43 39 39 43 4D 43 39 25 11 25 39 43 4D 43 39 11 25 39 43 4D 43 39 25 11 25 39 43 4D 4D 43 43 25 11 25 43 39 25 11 4D 43 39 39 43 4D 43 39 25 11 25 39 43 4D 43 39 11 25
		39 01 00 00 00 00 66 78 39 43 4D 43 39 25 11 25 39 43 4D 39 43 4D 43 39 25 11 25 39 43 4D 43 39 28 28 28 28 28 28 27 26 24 23 16 16 16 1F 1E 21 25 29 01 05 08 0B 0E 11 14 18 21 25 29 01 03 05 07 18 05 08 0B 0E 11 05 08 0B 1B 1E 21 25 29 01 05 08 0B 0E 28 28 28 28 28 28 27 26 24 23 16 16 16 21 25 29 01 03 05 07 18 05 08 0B 0E
		39 01 00 00 00 00 66 78 11 05 08 0B 1B 1E 21 25 29 01 05 08 0B 0E 01 05 08 0B 0E 11 14 18 1B 1E 21 25 29 28 28 28 28 28 28 27 26 24 23 16 16 16 05 08 0B 1B 1E 21 25 29 01 05 08 0B 0E 01 05 08 0B 0E 11 14 18 1B 1E 21 25 29 1B 1E 21 25 29 01 05 08 0B 0E 11 14 18 28 28 28 28 28 28 27 26 24 23 16 16 16 01 05 08 0B 0E 11 14 18 1B
		39 01 00 00 00 00 1F 78 1E 21 25 29 1B 1E 21 25 29 01 05 08 0B 0E 11 14 18 21 25 29 01 03 05 07 18 05 08 0B 0E 11
		39 01 00 00 00 00 02 FE 41
		39 01 00 00 00 00 02 D6 00
		15 01 00 00 00 00 02 FE 60
		15 01 00 00 00 00 02 88 0D
		15 01 00 00 00 00 02 91 0D
		15 01 00 00 00 00 02 9A 0D
		15 01 00 00 00 00 02 A4 0D
		15 01 00 00 00 00 02 FE 98
		15 01 00 00 00 00 02 13 06
		15 01 00 00 00 00 02 FE 36
		15 01 00 00 00 00 02 EC 00
		15 01 00 00 00 00 02 07 A0
		15 01 00 00 00 00 02 08 A0
		15 01 00 00 00 00 02 09 02
		15 01 00 00 00 00 02 FE A1
		15 01 00 00 00 00 02 B5 04
		15 01 00 00 00 00 02 FE 62
		15 01 00 00 00 00 02 4E 00
		15 01 00 00 00 00 02 FE 40
		15 01 00 00 00 00 02 B6 02
		15 01 00 00 00 00 02 23 00
		15 01 00 00 00 00 02 24 54
		15 01 00 00 00 00 02 47 22
		15 01 00 00 00 00 02 48 13
		15 01 00 00 00 00 02 FE FD
		15 01 00 00 00 00 02 80 F6
		15 01 00 00 00 00 02 FE D1
		15 01 00 00 00 00 02 F5 30
		15 01 00 00 00 00 02 F9 00
		15 01 00 00 00 00 02 F7 80
		15 01 00 00 00 00 02 FE 83
		15 01 00 00 00 00 02 0C 4F
		15 01 00 00 00 00 02 0D 7E
		15 01 00 00 00 00 02 0E FF
		15 01 00 00 00 00 02 0F 7E
		15 01 00 00 00 00 02 10 7E
		15 01 00 00 00 00 02 11 FF
		15 01 00 00 00 00 02 12 7E
		15 01 00 00 00 00 02 13 7E
		15 01 00 00 00 00 02 14 FF
		15 01 00 00 00 00 02 15 7E
		15 01 00 00 00 00 02 16 7E
		15 01 00 00 00 00 02 17 FF
		15 01 00 00 00 00 02 18 7E
		15 01 00 00 00 00 02 19 7E
		15 01 00 00 00 00 02 1A FF
		15 01 00 00 00 00 02 1B 7E
		15 01 00 00 00 00 02 1C 7E
		15 01 00 00 00 00 02 FE F9
		15 01 00 00 00 00 02 00 AF
		15 01 00 00 00 00 02 1D 1F
		15 01 00 00 00 00 02 FE 00
		15 01 00 00 00 00 02 FA 01
		15 01 00 00 00 00 02 C2 08
		15 01 00 00 00 00 02 35 00
		39 01 00 00 00 00 03 51 00 00
		15 01 00 00 00 00 02 FE 40
		15 01 00 00 00 00 02 BD 06
		15 01 00 00 00 00 02 FE 00
		05 01 00 00 78 00 01 11
		05 01 00 00 00 00 01 29];
				qcom,mdss-dsi-on-command-state = "dsi_lp_mode";
				qcom,mdss-dsi-off-command = [15 01 00 00 00 00 02 FE 00
			05 01 00 00 23 00 01 28
			05 01 00 00 64 00 01 10];
				qcom,mdss-dsi-off-command-state = "dsi_lp_mode";
				qcom,compression-mode = "dsc";
				qcom,mdss-dsc-slice-height = <60>;
				qcom,mdss-dsc-slice-width = <614>;
				qcom,mdss-dsc-slice-per-pkt = <2>;
				qcom,mdss-dsc-bit-per-component = <8>;
				qcom,mdss-dsc-bit-per-pixel = <8>;
				qcom,mdss-dsc-block-prediction-enable;
				qcom,mdss-dsi-timing-switch-command = [15 01 00 00 00 00 02 FE 40
			15 01 00 00 00 00 02 BD 06
			15 01 00 00 11 00 02 FE 00];
				qcom,mdss-dsi-timing-switch-command-state = "dsi_lp_mode";
				qcom,mdss-dsi-lp1-command = [15 01 00 00 00 00 02 FE 00
			05 01 00 00 00 00 01 39];
				qcom,mdss-dsi-lp1-command-state = "dsi_lp_mode";
				qcom,mdss-dsi-nolp-command = [15 01 00 00 00 00 02 FE 00
			39 01 00 00 00 00 03 51 00 00
			05 01 00 00 00 00 01 38
			15 01 00 00 00 00 02 FE 40
			15 01 00 00 00 00 02 BD 06
			15 01 00 00 11 00 02 FE 00];
				qcom,mdss-dsi-nolp-command-state = "dsi_lp_mode";
			};
			timing@2 {
				qcom,mdss-dsi-panel-width = <1228>;
				qcom,mdss-dsi-panel-height = <2700>;
				qcom,mdss-dsi-h-front-porch = <32>;
				qcom,mdss-dsi-h-back-porch = <32>;
				qcom,mdss-dsi-h-pulse-width = <32>;
				qcom,mdss-dsi-h-sync-skew = <0>;
				qcom,mdss-dsi-v-front-porch = <16>;
				qcom,mdss-dsi-v-back-porch = <12>;
				qcom,mdss-dsi-v-pulse-width = <4>;
				qcom,mdss-dsi-panel-framerate = <120>;
				qcom,mdss-dsi-panel-phy-timings= [00 22 08 08 19 17 09
			08 08 09 02 04 1C 0D];
				qcom,display-topology  = <2 2 1>;
				qcom,default-topology-index  = <0>;
				qcom,mdss-dsi-on-command = [
		39 01 00 00 00 00 02 FE 40
		39 01 00 00 00 00 02 24 55
		39 01 00 00 00 00 02 A9 14
		39 01 00 00 00 00 02 AD C8
		39 01 00 00 00 00 02 A5 20
		39 01 00 00 00 00 02 AC 04
		39 01 00 00 00 00 02 AE 70
		39 01 00 00 00 00 02 AF 00
		39 01 00 00 00 00 02 B0 00
		39 01 00 00 00 00 02 B2 00
		39 01 00 00 00 00 02 B3 50
		39 01 00 00 00 00 02 FE 26
		39 01 00 00 00 00 02 1D 2A
		39 01 00 00 00 00 02 A4 23
		39 01 00 00 00 00 02 FE 41
		39 01 00 00 00 00 02 D6 04
		39 01 00 00 00 00 02 FE 00
		39 01 00 00 00 00 65 77 4D 43 39 25 11 25 39 43 4D 43 39 25 11 11 25 39 43 4D 43 39 25 11 25 39 43 4D 39 43 4D 43 39 25 11 25 39 43 4D 43 39 4D 43 25 11 11 25 43 39 25 11 4D 43 39 11 25 39 43 4D 43 39 25 11 25 39 43 4D 39 43 4D 43 39 25 11 25 39 43 4D 43 39 4D 43 25 11 11 25 43 39 25 11 4D 43 39 4D 43 39 25 11 25 39 43 4D
		39 01 00 00 00 00 65 78 43 39 25 11 39 43 4D 43 39 25 11 25 39 43 4D 43 39 4D 43 25 11 11 25 43 39 25 11 4D 43 39 4D 43 39 25 11 25 39 43 4D 43 39 25 11 11 25 39 43 4D 43 39 25 11 25 39 43 4D 4D 43 25 11 11 25 43 39 25 11 4D 43 39 4D 43 39 25 11 25 39 43 4D 43 39 25 11 11 25 39 43 4D 43 39 25 11 25 39 43 4D 39 43 4D 43 39
		39 01 00 00 00 00 65 78 25 11 25 39 43 4D 43 39 11 25 39 43 4D 43 39 25 11 25 39 4B 4D 4D 43 39 25 11 25 39 43 4D 43 39 25 11 39 43 4D 43 39 25 11 25 39 43 4D 43 39 43 39 25 11 4D 43 43 25 11 25 39 43 4D 4D 43 39 25 11 25 39 43 4D 43 39 25 11 39 43 4D 43 39 25 11 25 39 43 4D 43 39 43 39 25 11 4D 43 43 25 11 25 39 43 4D 11
		39 01 00 00 00 00 65 78 25 39 43 4D 43 39 25 11 25 39 43 4D 39 43 4D 43 39 25 11 25 39 43 4D 43 39 43 39 25 11 4D 43 43 25 11 25 39 43 4D 11 25 39 43 4D 43 39 25 11 25 39 43 4D 4D 43 39 25 11 25 39 43 4D 43 39 25 11 43 39 25 11 4D 43 43 25 11 25 39 43 4D 11 25 39 43 4D 43 39 25 11 25 39 43 4D 4D 43 39 25 11 25 39 43 4D 43
		39 01 00 00 00 00 65 78 39 25 11 39 43 4D 43 39 25 11 25 39 43 4D 43 39 39 43 4D 43 39 25 11 25 39 43 4D 43 39 11 25 39 43 4D 43 39 25 11 25 39 43 4D 39 43 4D 43 39 25 11 25 39 43 4D 43 39 4D 43 43 25 11 25 43 39 25 11 4D 43 39 11 25 39 43 4D 43 39 25 11 25 39 43 4D 39 43 4D 43 39 25 11 25 39 43 4D 43 39 4D 43 43 25 11 25
		39 01 00 00 00 00 65 78 43 39 25 11 4D 43 39 39 43 4D 43 39 25 11 25 39 43 4D 43 39 39 43 4D 43 39 25 11 25 39 43 4D 43 39 4D 43 43 25 11 25 43 39 25 11 4D 43 39 39 43 4D 43 39 25 11 25 39 43 4D 43 39 11 25 39 43 4D 43 39 25 11 25 39 43 4D 4D 43 43 25 11 25 43 39 25 11 4D 43 39 39 43 4D 43 39 25 11 25 39 43 4D 43 39 11 25
		39 01 00 00 00 00 66 78 39 43 4D 43 39 25 11 25 39 43 4D 39 43 4D 43 39 25 11 25 39 43 4D 43 39 28 28 28 28 28 28 27 26 24 23 16 16 16 1F 1E 21 25 29 01 05 08 0B 0E 11 14 18 21 25 29 01 03 05 07 18 05 08 0B 0E 11 05 08 0B 1B 1E 21 25 29 01 05 08 0B 0E 28 28 28 28 28 28 27 26 24 23 16 16 16 21 25 29 01 03 05 07 18 05 08 0B 0E
		39 01 00 00 00 00 66 78 11 05 08 0B 1B 1E 21 25 29 01 05 08 0B 0E 01 05 08 0B 0E 11 14 18 1B 1E 21 25 29 28 28 28 28 28 28 27 26 24 23 16 16 16 05 08 0B 1B 1E 21 25 29 01 05 08 0B 0E 01 05 08 0B 0E 11 14 18 1B 1E 21 25 29 1B 1E 21 25 29 01 05 08 0B 0E 11 14 18 28 28 28 28 28 28 27 26 24 23 16 16 16 01 05 08 0B 0E 11 14 18 1B
		39 01 00 00 00 00 1F 78 1E 21 25 29 1B 1E 21 25 29 01 05 08 0B 0E 11 14 18 21 25 29 01 03 05 07 18 05 08 0B 0E 11
		39 01 00 00 00 00 02 FE 41
		39 01 00 00 00 00 02 D6 00
		15 01 00 00 00 00 02 FE 60
		15 01 00 00 00 00 02 88 0D
		15 01 00 00 00 00 02 91 0D
		15 01 00 00 00 00 02 9A 0D
		15 01 00 00 00 00 02 A4 0D
		15 01 00 00 00 00 02 FE 98
		15 01 00 00 00 00 02 13 06
		15 01 00 00 00 00 02 FE 36
		15 01 00 00 00 00 02 EC 00
		15 01 00 00 00 00 02 07 A0
		15 01 00 00 00 00 02 08 A0
		15 01 00 00 00 00 02 09 02
		15 01 00 00 00 00 02 FE A1
		15 01 00 00 00 00 02 B5 04
		15 01 00 00 00 00 02 FE 62
		15 01 00 00 00 00 02 4E 00
		15 01 00 00 00 00 02 FE 40
		15 01 00 00 00 00 02 B6 02
		15 01 00 00 00 00 02 23 00
		15 01 00 00 00 00 02 24 54
		15 01 00 00 00 00 02 47 22
		15 01 00 00 00 00 02 48 13
		15 01 00 00 00 00 02 FE FD
		15 01 00 00 00 00 02 80 F6
		15 01 00 00 00 00 02 FE D1
		15 01 00 00 00 00 02 F5 30
		15 01 00 00 00 00 02 F9 00
		15 01 00 00 00 00 02 F7 80
		15 01 00 00 00 00 02 FE 83
		15 01 00 00 00 00 02 0C 4F
		15 01 00 00 00 00 02 0D 7E
		15 01 00 00 00 00 02 0E FF
		15 01 00 00 00 00 02 0F 7E
		15 01 00 00 00 00 02 10 7E
		15 01 00 00 00 00 02 11 FF
		15 01 00 00 00 00 02 12 7E
		15 01 00 00 00 00 02 13 7E
		15 01 00 00 00 00 02 14 FF
		15 01 00 00 00 00 02 15 7E
		15 01 00 00 00 00 02 16 7E
		15 01 00 00 00 00 02 17 FF
		15 01 00 00 00 00 02 18 7E
		15 01 00 00 00 00 02 19 7E
		15 01 00 00 00 00 02 1A FF
		15 01 00 00 00 00 02 1B 7E
		15 01 00 00 00 00 02 1C 7E
		15 01 00 00 00 00 02 FE F9
		15 01 00 00 00 00 02 00 AF
		15 01 00 00 00 00 02 1D 1F
		15 01 00 00 00 00 02 FE 00
		15 01 00 00 00 00 02 FA 01
		15 01 00 00 00 00 02 C2 08
		15 01 00 00 00 00 02 35 00
		39 01 00 00 00 00 03 51 00 00
		15 01 00 00 00 00 02 FE 40
		15 01 00 00 00 00 02 BD 05
		15 01 00 00 00 00 02 FE 00
		05 01 00 00 78 00 01 11
		05 01 00 00 00 00 01 29];
				qcom,mdss-dsi-on-command-state = "dsi_lp_mode";
				qcom,mdss-dsi-off-command = [15 01 00 00 00 00 02 FE 00
			05 01 00 00 23 00 01 28
			05 01 00 00 64 00 01 10];
				qcom,mdss-dsi-off-command-state = "dsi_lp_mode";
				qcom,compression-mode = "dsc";
				qcom,mdss-dsc-slice-height = <60>;
				qcom,mdss-dsc-slice-width = <614>;
				qcom,mdss-dsc-slice-per-pkt = <2>;
				qcom,mdss-dsc-bit-per-component = <8>;
				qcom,mdss-dsc-bit-per-pixel = <8>;
				qcom,mdss-dsc-block-prediction-enable;
				qcom,mdss-dsi-timing-switch-command = [15 01 00 00 00 00 02 FE 40
			15 01 00 00 00 00 02 BD 05
			15 01 00 00 00 00 02 FE 00];
				qcom,mdss-dsi-timing-switch-command-state = "dsi_lp_mode";
				qcom,mdss-dsi-lp1-command = [15 01 00 00 00 00 02 FE 00
			05 01 00 00 00 00 01 39];
				qcom,mdss-dsi-lp1-command-state = "dsi_lp_mode";
				qcom,mdss-dsi-nolp-command = [15 01 00 00 00 00 02 FE 00
			39 01 00 00 00 00 03 51 00 00
			05 01 00 00 00 00 01 38
			15 01 00 00 00 00 02 FE 40
			15 01 00 00 00 00 02 BD 05
			15 01 00 00 00 00 02 FE 00];
				qcom,mdss-dsi-nolp-command-state = "dsi_lp_mode";
			};
		};
    };
};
